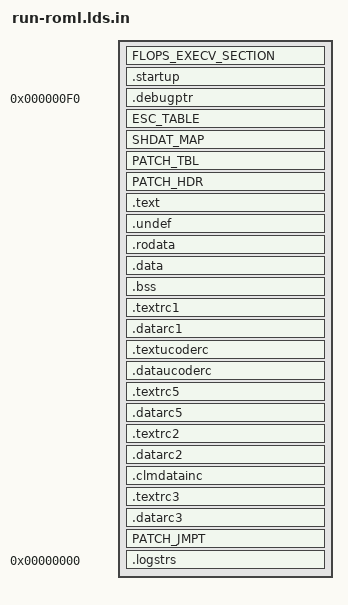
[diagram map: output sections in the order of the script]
OUTPUT_ARCH(TARGET_ARCH)
ENTRY(startup)
SECTIONS {

	FLOPS_EXECV_SECTION

	/* Boot section for startup and exception vectors */
	. = TEXT_START;
	.startup : {
		BOOTLOADER_PATCH_MEM
		_ftext = .;
		text_start = .;
		*(.text.startup)
	}

	/* Special place for debug info to make it easy to find */
	.debugptr 0xf0 : {
		KEEP(*(.text.debugptr))
		*(.text.debugptr)
	}

	/* Reclaim memory that provides compatibility with builds that require the bootloader
	 * patch section.
	 */
	_rstart4 = .;

	. = DATA_START;
	_rend4 = .;

	/* ROM escape table */
	ESC_TABLE

	/* Data section shared by RAM and ROM */
	SHDAT_MAP

	PATCH_TBL

	PATCH_HDR
	/* Code section for regular code */
	.text : {
		*(.init)
		*(.text)
		*(.text.*)
		*(.textrom.*)
		*(.fini)
		*(.glue_7)
		*(.glue_7t)
		ESC_KEEP
	}
	/* Special section for undefined symbols due to different compiler flags */
	.undef : {
		UNDEF_MAP
		_etext = .;
		text_end = .;
	}


	.rodata : {
		rodata_start = .;
		*(.rdata)
		*(.rdata.*)
		*(.rodata)
		*(.rodata.*)
		*(.datarom.*)
		rodata_end = .;
	}

	/* Data sections for regular initialized/uninitialized data */
	.data : {
		_fdata = .;
		data_start = .;
		*(.data)
		*(.data.*)
		*(.sdata)
		_edata = .;
		data_end = .;
	}
	.bss : {
		_fbss = .;
		bss_start = .;
		*(.scommon)
		*(.bss)
		*(.bss.*)
		*(.sbss)
		*(COMMON)
		bss_end = .;
	}

	/* Reclaim region 1 for BCMINITFN/BCMINITDATA */
	.textrc1 : {
		_rstart1 = .;
		*(.textini1.*)
		ESC1_KEEP
	}
	.datarc1 : {
		*(.rodataini1.*)
		*(.dataini1.*)
		. = ALIGN(4);
		_rend1 = .;
	}

	/* Reclaim region for BCMUCODEDATA/BCMUCODEFN */
	.textucoderc : {
		. = ALIGN(4);
		ucodes_start = .;
		*(.textucode.*)
	}
	.dataucoderc : {
		*(.rodataucode.*)
		*(.dataucode.*)
		. = ALIGN(4);
		ucodes_end = .;
	}

	/* Reclaim region 5 for BCMPOSTATTACHDATA/BCMPOSTATTACHFN */
	.textrc5 : {
		. = ALIGN(4);
		_rstart5 = .;
		*(.textini5.*)
	}
	.datarc5 : {
		*(.rodataini5.*)
		*(.dataini5.*)
		. = ALIGN(4);
		_rend5 = .;
	}

	/* Reclaim region 2 for BCMATTACHFN/BCMATTACHDATA */
	.textrc2 : {
		_rstart2 = .;
		*(.textini2.*)
		ESC2_KEEP
	}
	.datarc2 : {
		. = ALIGN(4);
		*(.rodataini2*)
		*(.rodataini2.*)
		*(.dataini2.*)

		/* Align _rend2 so that it is contiguous with the next section. This allows the
		 * 2 sections to be joined into a single free heap block after both sections have
		 * been reclaimed. This helps avoid fragmentation.
		 */
		. = ALIGN(4);
		_rend2 = .;
	}

	/* Place CLM incremental data in its own data section (instead of reclaim region 2
	 * ".datarc2") so that it can be reclaimed immediately after copying data to a malloc'ed
	 * buffer. This avoids holding onto 2 copies of the incremental data during
	 * attach time, and frees up more heap space for attach time allocations.
	 */
	.clmdatainc : {
		. = ALIGN(4);
		_clmincstart = .;
		*(.clmdataini2.*)
		_clmincend = .;
	}

	/* Reclaim region 3 for BCMPREATTACHDATA/BCMPREATTACHFN */
	.textrc3 : {
		_rstart3 = .;
		*(.textini3.*)
		ESC3_KEEP
	}
	.datarc3 : {
		*(.rodataini3.*)
		*(.dataini3.*)
		. = ALIGN(4);
		_rend3 = .;
	}

	_end = .;

	PATCH_JMPT

	.logstrs 0 (OVERLAY) : {
		rom_lognums_offset = .;
		KEEP(*(.romlognums))
		ram_lognums_offset = .;
		KEEP(*(.lognums))
		rom_logstrs_offset = .;
		KEEP(*(.romlogstrs))
		ram_logstrs_offset = .;
		KEEP(*(.logstrs))

		/* Header */
		. = ALIGN(4);
		LONG(logstrs_size)		/* Size of this file */
		LONG(rom_lognums_offset)
		LONG(ram_lognums_offset)
		LONG(rom_logstrs_offset)
		LONG(ram_logstrs_offset)
		LONG(1)				/* Header version */
		LONG(0x4C4F4753)	/* MAGIC number for verification 'LOGS' */
		logstrs_size = .;
	}

}
